# MKE15Z7 register map
Vendor: Freescale Semiconductor, Inc.; Series: Kinetis_E; File version: 1.6
CPU: CM0PLUS r0p0, little endian, no MPU, no FPU, VTOR, 2 interrupt priority bits
Registers are 32-bit, read-write, reset 0x0 unless marked. A register's access mark holds for its fields unless they carry their own. Offsets are from the block's base; [hi:lo] are bit positions; {n}, {i} and the like mark numbered series; 'fields as' and 'values as' point back to an identical list.

## PORTA — Pin Control and Interrupts
Base 0x40049000; register names take the prefix PORTA_
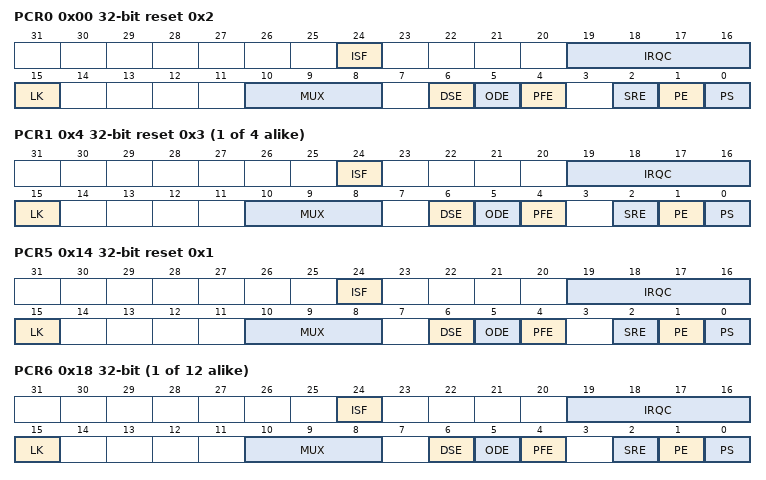
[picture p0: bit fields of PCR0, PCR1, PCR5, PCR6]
0x00 PCR0 reset 0x2 — Pin Control Register n
  [24] ISF — Interrupt Status Flag
    0=Configured interrupt is not detected; 1=Configured interrupt is detected. If the pin is configured to generate a DMA request, then the corresponding flag will be cleared automatically at the completion of the requested DMA transfer. Otherwise, the flag remains set until a logic 1 is written to the flag. If the pin is configured for a level sensitive interrupt and the pin remains asserted, then the flag is set again immediately after it is cleared.
  [19:16] IRQC — Interrupt Configuration
    0=Interrupt Status Flag (ISF) is disabled; 1=ISF flag and DMA request on rising edge; 2=ISF flag and DMA request on falling edge; 3=ISF flag and DMA request on either edge; 8=ISF flag and Interrupt when logic 0; 9=ISF flag and Interrupt on rising-edge; 10=ISF flag and Interrupt on falling-edge; 11=ISF flag and Interrupt on either edge; 12=ISF flag and Interrupt when logic 1
  [15] LK — Lock Register
    0=Pin Control Register fields [15:0] are not locked; 1=Pin Control Register fields [15:0] are locked and cannot be updated until the next system reset
  [10:8] MUX — Pin Mux Control
    0=Pin disabled (Alternative 0) (analog); 1=Alternative 1 (GPIO); {v}=Alternative {v} (chip-specific) (v=2..7)
  [6] DSE — Drive Strength Enable
    0=Low drive strength is configured on the corresponding pin, if pin is configured as a digital output; 1=High drive strength is configured on the corresponding pin, if pin is configured as a digital output
  [5] ODE — Open Drain Enable
    0=Open drain output is disabled on the corresponding pin; 1=Open drain output is enabled on the corresponding pin, if the pin is configured as a digital output
  [4] PFE — Passive Filter Enable
    0=Passive input filter is disabled on the corresponding pin; 1=Passive input filter is enabled on the corresponding pin, if the pin is configured as a digital input. Refer to the device data sheet for filter characteristics.
  [2] SRE — Slew Rate Enable
    0=Fast slew rate is configured on the corresponding pin, if the pin is configured as a digital output; 1=Slow slew rate is configured on the corresponding pin, if the pin is configured as a digital output
  [1] PE — Pull Enable
    0=Internal pullup or pulldown resistor is not enabled on the corresponding pin; 1=Internal pullup or pulldown resistor is enabled on the corresponding pin, if the pin is configured as a digital input
  [0] PS — Pull Select
    0=Internal pulldown resistor is enabled on the corresponding pin, if the corresponding PE field is set; 1=Internal pullup resistor is enabled on the corresponding pin, if the corresponding PE field is set
{0x0+4i} PCR{i} reset 0x3 (i=1..4) — Pin Control Register n
  fields as PCR0
0x14 PCR5 reset 0x1 — Pin Control Register n
  fields as PCR0
{0x0+4i} PCR{i} (i=6..17) — Pin Control Register n
  fields as PCR0
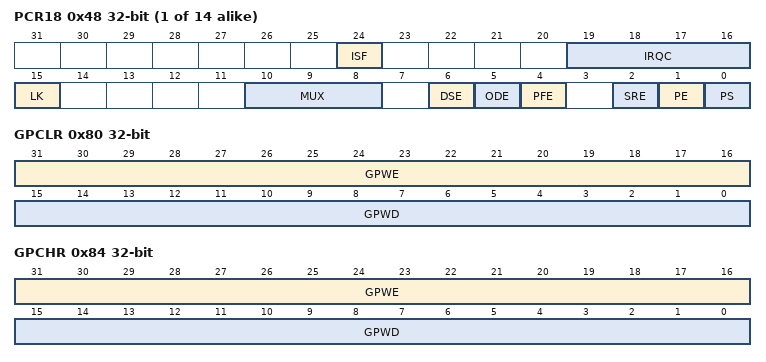
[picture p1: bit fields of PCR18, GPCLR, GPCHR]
{0x0+4i} PCR{i} (i=18..31) — Pin Control Register n
  [24] ISF — Interrupt Status Flag
    values as PCR0.ISF
  [19:16] IRQC — Interrupt Configuration
    values as PCR0.IRQC
  [15] LK — Lock Register
    values as PCR0.LK
  [10:8] MUX — Pin Mux Control
    values as PCR0.MUX
  [6] DSE ro — Drive Strength Enable
    values as PCR0.DSE
  [5] ODE ro — Open Drain Enable
    values as PCR0.ODE
  [4] PFE ro — Passive Filter Enable
    values as PCR0.PFE
  [2] SRE ro — Slew Rate Enable
    values as PCR0.SRE
  [1] PE ro — Pull Enable
    values as PCR0.PE
  [0] PS ro — Pull Select
    values as PCR0.PS
0x80 GPCLR wo — Global Pin Control Low Register
  [31:16] GPWE — Global Pin Write Enable
    0=Corresponding Pin Control Register is not updated with the value in GPWD; 1=Corresponding Pin Control Register is updated with the value in GPWD
  [15:0] GPWD — Global Pin Write Data
0x84 GPCHR wo — Global Pin Control High Register
  fields as GPCLR
0xA0 ISFR — Interrupt Status Flag Register
  [31:0] ISF — Interrupt Status Flag
    values as PCR0.ISF
0xC0 DFER — Digital Filter Enable Register
  [31:0] DFE — Digital Filter Enable
    0=Digital filter is disabled on the corresponding pin and output of the digital filter is reset to zero; 1=Digital filter is enabled on the corresponding pin, if the pin is configured as a digital input
0xC4 DFCR — Digital Filter Clock Register
  [0] CS — Clock Source
    0=Digital filters are clocked by the bus clock; 1=Digital filters are clocked by the LPO clock
0xC8 DFWR — Digital Filter Width Register
  [4:0] FILT — Filter Length

## PORTB — Pin Control and Interrupts
Base 0x4004A000; register names take the prefix PORTB_
Registers as PORTA; these are added or differ:
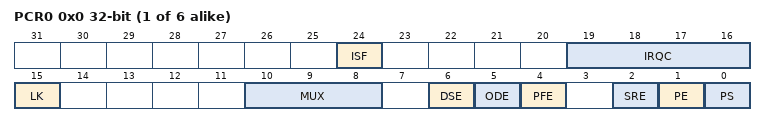
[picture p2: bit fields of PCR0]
{0x0+4i} PCR{i} (i=0..5) — Pin Control Register n
  fields as PORTA.PCR0

## PORTC — Pin Control and Interrupts
Base 0x4004B000; register names take the prefix PORTC_
Registers as PORTB.

## PORTD — Pin Control and Interrupts
Base 0x4004C000; register names take the prefix PORTD_
Registers as PORTB.

## PORTE — Pin Control and Interrupts
Base 0x4004D000; register names take the prefix PORTE_
Registers as PORTB; these are added or differ:
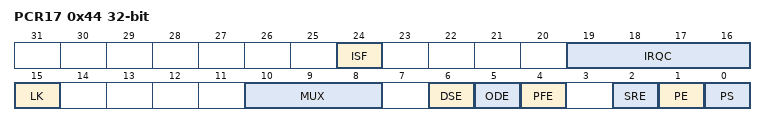
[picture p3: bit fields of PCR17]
0x44 PCR17 — Pin Control Register n
  fields as PORTA.PCR18
